# ESP32-S2 register map
Vendor: ESPRESSIF SYSTEMS (SHANGHAI) CO., LTD.; Series: ESP32 S-Series; File version: 20
CPU: Xtensa LX7 r0p0, little endian, no MPU, no FPU, 0 interrupt priority bits
Address unit: 32 bits
Registers are 32-bit, read-write, reset 0x0 unless marked. A register's access mark holds for its fields unless they carry their own. Offsets are from the block's base; [hi:lo] are bit positions.

## EXTMEM — External Memory
Base 0x61800000
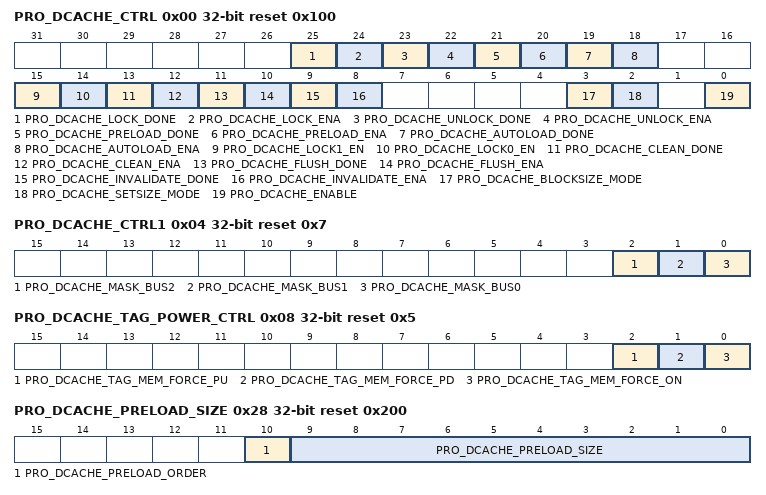
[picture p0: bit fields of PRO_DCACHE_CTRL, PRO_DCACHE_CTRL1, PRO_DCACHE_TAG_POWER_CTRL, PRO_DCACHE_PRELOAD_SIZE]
0x00 PRO_DCACHE_CTRL access per field reset 0x100 — register description
  [25] PRO_DCACHE_LOCK_DONE ro — The bit is used to indicate lock operation is finished.
  [24] PRO_DCACHE_LOCK_ENA rw — The bit is used to enable lock operation. It will be cleared by hardware after lock operation done.
  [23] PRO_DCACHE_UNLOCK_DONE ro — The bit is used to indicate unlock operation is finished.
  [22] PRO_DCACHE_UNLOCK_ENA rw — The bit is used to enable unlock operation. It will be cleared by hardware after unlock operation done.
  [21] PRO_DCACHE_PRELOAD_DONE ro — The bit is used to indicate preload operation is finished.
  [20] PRO_DCACHE_PRELOAD_ENA rw — The bit is used to enable preload operation. It will be cleared by hardware after preload operation done.
  [19] PRO_DCACHE_AUTOLOAD_DONE ro — The bit is used to indicate conditional-preload operation is finished.
  [18] PRO_DCACHE_AUTOLOAD_ENA rw — The bit is used to enable and disable conditional-preload operation. It is combined with pre_dcache_autoload_done. 1: enable, 0: disable.
  [15] PRO_DCACHE_LOCK1_EN rw — The bit is used to enable pre-lock operation which is combined with PRO_DCACHE_LOCK1_ADDR_REG and PRO_DCACHE_LOCK1_SIZE_REG.
  [14] PRO_DCACHE_LOCK0_EN rw — The bit is used to enable pre-lock operation which is combined with PRO_DCACHE_LOCK0_ADDR_REG and PRO_DCACHE_LOCK0_SIZE_REG.
  [13] PRO_DCACHE_CLEAN_DONE ro — The bit is used to indicate clean operation is finished.
  [12] PRO_DCACHE_CLEAN_ENA rw — The bit is used to enable clean operation. It will be cleared by hardware after clean operation done.
  [11] PRO_DCACHE_FLUSH_DONE ro — The bit is used to indicate flush operation is finished.
  [10] PRO_DCACHE_FLUSH_ENA rw — The bit is used to enable flush operation. It will be cleared by hardware after flush operation done.
  [9] PRO_DCACHE_INVALIDATE_DONE ro — The bit is used to indicate invalidate operation is finished.
  [8] PRO_DCACHE_INVALIDATE_ENA rw — The bit is used to enable invalidate operation. It will be cleared by hardware after invalidate operation done.
  [3] PRO_DCACHE_BLOCKSIZE_MODE rw — The bit is used to configure cache block size.0: 16 bytes, 1: 32 bytes
  [2] PRO_DCACHE_SETSIZE_MODE rw — The bit is used to configure cache memory size.0: 8KB, 1: 16KB
  [0] PRO_DCACHE_ENABLE rw — The bit is used to activate the data cache. 0: disable, 1: enable
0x04 PRO_DCACHE_CTRL1 reset 0x7 — register description
  [2] PRO_DCACHE_MASK_BUS2 — The bit is used to disable dbus2, 0: enable, 1: disable
  [1] PRO_DCACHE_MASK_BUS1 — The bit is used to disable dbus1, 0: enable, 1: disable
  [0] PRO_DCACHE_MASK_BUS0 — The bit is used to disable dbus0, 0: enable, 1: disable
0x08 PRO_DCACHE_TAG_POWER_CTRL reset 0x5 — register description
  [2] PRO_DCACHE_TAG_MEM_FORCE_PU — The bit is used to power dcache tag memory down, 0: follow rtc_lslp_pd, 1: power up
  [1] PRO_DCACHE_TAG_MEM_FORCE_PD — The bit is used to power dcache tag memory down, 0: follow rtc_lslp_pd, 1: power down
  [0] PRO_DCACHE_TAG_MEM_FORCE_ON — The bit is used to close clock gating of dcache tag memory. 1: close gating, 0: open clock gating.
0x0C PRO_DCACHE_LOCK0_ADDR — register description
  [31:0] PRO_DCACHE_LOCK0_ADDR — The bits are used to configure the first start virtual address of data locking, which is combined with PRO_DCACHE_LOCK0_SIZE_REG
0x10 PRO_DCACHE_LOCK0_SIZE — register description
  [15:0] PRO_DCACHE_LOCK0_SIZE — The bits are used to configure the first length of data locking, which is combined with PRO_DCACHE_LOCK0_ADDR_REG
0x14 PRO_DCACHE_LOCK1_ADDR — register description
  [31:0] PRO_DCACHE_LOCK1_ADDR — The bits are used to configure the second start virtual address of data locking, which is combined with PRO_DCACHE_LOCK1_SIZE_REG
0x18 PRO_DCACHE_LOCK1_SIZE — register description
  [15:0] PRO_DCACHE_LOCK1_SIZE — The bits are used to configure the second length of data locking, which is combined with PRO_DCACHE_LOCK1_ADDR_REG
0x1C PRO_DCACHE_MEM_SYNC0 — register description
  [31:0] PRO_DCACHE_MEMSYNC_ADDR — The bits are used to configure the start virtual address for invalidate, flush, clean, lock and unlock operations. The manual operations will be issued if the address is validate. The auto operations will be issued if the address is invalidate. It should be combined with PRO_DCACHE_MEM_SYNC1.
0x20 PRO_DCACHE_MEM_SYNC1 — register description
  [18:0] PRO_DCACHE_MEMSYNC_SIZE — The bits are used to configure the length for invalidate, flush, clean, lock and unlock operations. The manual operations will be issued if it is validate. The auto operations will be issued if it is invalidate. It should be combined with PRO_DCACHE_MEM_SYNC0.
0x24 PRO_DCACHE_PRELOAD_ADDR — register description
  [31:0] PRO_DCACHE_PRELOAD_ADDR — The bits are used to configure the start virtual address for manual pre-load operation. It should be combined with PRO_DCACHE_PRELOAD_SIZE_REG.
0x28 PRO_DCACHE_PRELOAD_SIZE reset 0x200 — register description
  [10] PRO_DCACHE_PRELOAD_ORDER — The bits are used to configure the direction of manual pre-load operation. 1: descending, 0: ascending.
  [9:0] PRO_DCACHE_PRELOAD_SIZE — The bits are used to configure the length for manual pre-load operation. It should be combined with PRO_DCACHE_PRELOAD_ADDR_REG..
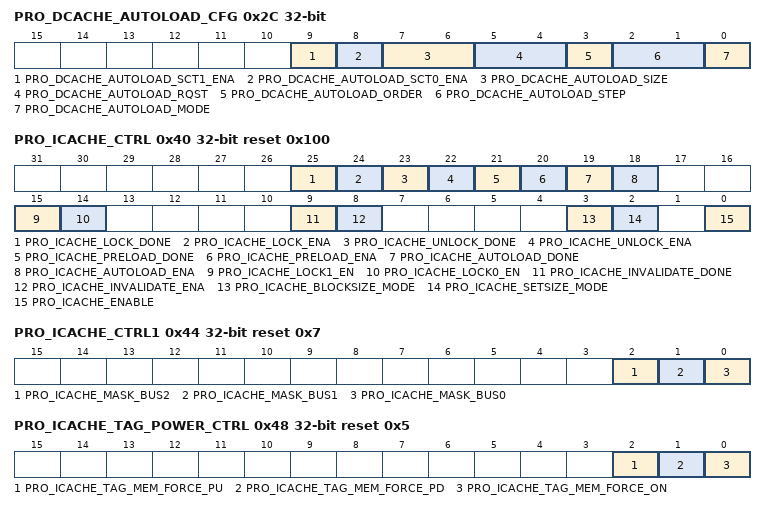
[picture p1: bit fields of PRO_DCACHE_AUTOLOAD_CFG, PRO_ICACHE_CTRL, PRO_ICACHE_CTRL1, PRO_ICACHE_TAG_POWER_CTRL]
0x2C PRO_DCACHE_AUTOLOAD_CFG — register description
  [9] PRO_DCACHE_AUTOLOAD_SCT1_ENA — The bits are used to enable the first section for conditional pre-load operation.
  [8] PRO_DCACHE_AUTOLOAD_SCT0_ENA — The bits are used to enable the second section for conditional pre-load operation.
  [7:6] PRO_DCACHE_AUTOLOAD_SIZE — The bits are used to configure the numbers of the cache block for the issuing conditional pre-load operation.
  [5:4] PRO_DCACHE_AUTOLOAD_RQST — The bits are used to configure trigger conditions for conditional pre-load. 0/3: cache miss, 1: cache hit, 2: both cache miss and hit.
  [3] PRO_DCACHE_AUTOLOAD_ORDER — The bits are used to configure the direction of conditional pre-load operation. 1: descending, 0: ascending.
  [2:1] PRO_DCACHE_AUTOLOAD_STEP — Reserved.
  [0] PRO_DCACHE_AUTOLOAD_MODE — Reserved.
0x30 PRO_DCACHE_AUTOLOAD_SECTION0_ADDR — register description
  [31:0] PRO_DCACHE_AUTOLOAD_SCT0_ADDR — The bits are used to configure the start virtual address of the first section for conditional pre-load operation. It should be combined with pro_dcache_autoload_sct0_ena.
0x34 PRO_DCACHE_AUTOLOAD_SECTION0_SIZE reset 0x8000 — register description
  [23:0] PRO_DCACHE_AUTOLOAD_SCT0_SIZE — The bits are used to configure the length of the first section for conditional pre-load operation. It should be combined with pro_dcache_autoload_sct0_ena.
0x38 PRO_DCACHE_AUTOLOAD_SECTION1_ADDR — register description
  [31:0] PRO_DCACHE_AUTOLOAD_SCT1_ADDR — The bits are used to configure the start virtual address of the second section for conditional pre-load operation. It should be combined with pro_dcache_autoload_sct1_ena.
0x3C PRO_DCACHE_AUTOLOAD_SECTION1_SIZE reset 0x8000 — register description
  [23:0] PRO_DCACHE_AUTOLOAD_SCT1_SIZE — The bits are used to configure the length of the second section for conditional pre-load operation. It should be combined with pro_dcache_autoload_sct1_ena.
0x40 PRO_ICACHE_CTRL access per field reset 0x100 — register description
  [25] PRO_ICACHE_LOCK_DONE ro — The bit is used to indicate lock operation is finished.
  [24] PRO_ICACHE_LOCK_ENA rw — The bit is used to enable lock operation. It will be cleared by hardware after lock operation done.
  [23] PRO_ICACHE_UNLOCK_DONE ro — The bit is used to indicate unlock operation is finished.
  [22] PRO_ICACHE_UNLOCK_ENA rw — The bit is used to enable unlock operation. It will be cleared by hardware after unlock operation done.
  [21] PRO_ICACHE_PRELOAD_DONE ro — The bit is used to indicate preload operation is finished.
  [20] PRO_ICACHE_PRELOAD_ENA rw — The bit is used to enable preload operation. It will be cleared by hardware after preload operation done.
  [19] PRO_ICACHE_AUTOLOAD_DONE ro — The bit is used to indicate conditional-preload operation is finished.
  [18] PRO_ICACHE_AUTOLOAD_ENA rw — The bit is used to enable and disable conditional-preload operation. It is combined with pre_dcache_autoload_done. 1: enable, 0: disable.
  [15] PRO_ICACHE_LOCK1_EN rw — The bit is used to enable pre-lock operation which is combined with PRO_ICACHE_LOCK1_ADDR_REG and PRO_ICACHE_LOCK1_SIZE_REG.
  [14] PRO_ICACHE_LOCK0_EN rw — The bit is used to enable pre-lock operation which is combined with PRO_ICACHE_LOCK0_ADDR_REG and PRO_ICACHE_LOCK0_SIZE_REG.
  [9] PRO_ICACHE_INVALIDATE_DONE ro — The bit is used to indicate invalidate operation is finished.
  [8] PRO_ICACHE_INVALIDATE_ENA rw — The bit is used to enable invalidate operation. It will be cleared by hardware after invalidate operation done.
  [3] PRO_ICACHE_BLOCKSIZE_MODE rw — The bit is used to configure cache block size.0: 16 bytes, 1: 32 bytes
  [2] PRO_ICACHE_SETSIZE_MODE rw — The bit is used to configure cache memory size.0: 8KB, 1: 16KB
  [0] PRO_ICACHE_ENABLE rw — The bit is used to activate the data cache. 0: disable, 1: enable
0x44 PRO_ICACHE_CTRL1 reset 0x7 — register description
  [2] PRO_ICACHE_MASK_BUS2 — The bit is used to disable ibus2, 0: enable, 1: disable
  [1] PRO_ICACHE_MASK_BUS1 — The bit is used to disable ibus1, 0: enable, 1: disable
  [0] PRO_ICACHE_MASK_BUS0 — The bit is used to disable ibus0, 0: enable, 1: disable
0x48 PRO_ICACHE_TAG_POWER_CTRL reset 0x5 — register description
  [2] PRO_ICACHE_TAG_MEM_FORCE_PU — The bit is used to power icache tag memory down, 0: follow rtc_lslp, 1: power up
  [1] PRO_ICACHE_TAG_MEM_FORCE_PD — The bit is used to power icache tag memory down, 0: follow rtc_lslp, 1: power down
  [0] PRO_ICACHE_TAG_MEM_FORCE_ON — The bit is used to close clock gating of icache tag memory. 1: close gating, 0: open clock gating.
0x4C PRO_ICACHE_LOCK0_ADDR — register description
  [31:0] PRO_ICACHE_LOCK0_ADDR — The bits are used to configure the first start virtual address of data locking, which is combined with PRO_ICACHE_LOCK0_SIZE_REG
0x50 PRO_ICACHE_LOCK0_SIZE — register description
  [15:0] PRO_ICACHE_LOCK0_SIZE — The bits are used to configure the first length of data locking, which is combined with PRO_ICACHE_LOCK0_ADDR_REG
0x54 PRO_ICACHE_LOCK1_ADDR — register description
  [31:0] PRO_ICACHE_LOCK1_ADDR — The bits are used to configure the second start virtual address of data locking, which is combined with PRO_ICACHE_LOCK1_SIZE_REG
0x58 PRO_ICACHE_LOCK1_SIZE — register description
  [15:0] PRO_ICACHE_LOCK1_SIZE — The bits are used to configure the second length of data locking, which is combined with PRO_ICACHE_LOCK1_ADDR_REG
0x5C PRO_ICACHE_MEM_SYNC0 — register description
  [31:0] PRO_ICACHE_MEMSYNC_ADDR — The bits are used to configure the start virtual address for invalidate, flush, clean, lock and unlock operations. The manual operations will be issued if the address is validate. The auto operations will be issued if the address is invalidate. It should be combined with PRO_ICACHE_MEM_SYNC1.
0x60 PRO_ICACHE_MEM_SYNC1 — register description
  [18:0] PRO_ICACHE_MEMSYNC_SIZE — The bits are used to configure the length for invalidate, flush, clean, lock and unlock operations. The manual operations will be issued if it is validate. The auto operations will be issued if it is invalidate. It should be combined with PRO_ICACHE_MEM_SYNC0.
0x64 PRO_ICACHE_PRELOAD_ADDR — register description
  [31:0] PRO_ICACHE_PRELOAD_ADDR — The bits are used to configure the start virtual address for manual pre-load operation. It should be combined with PRO_ICACHE_PRELOAD_SIZE_REG.
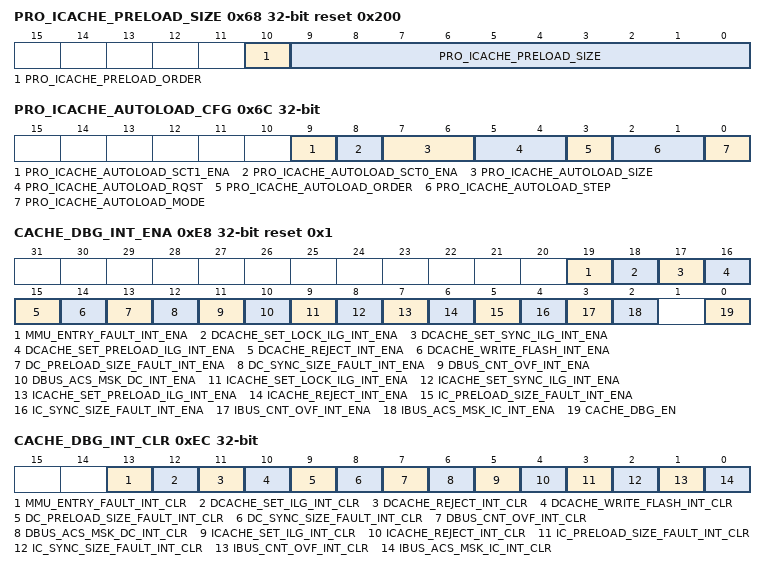
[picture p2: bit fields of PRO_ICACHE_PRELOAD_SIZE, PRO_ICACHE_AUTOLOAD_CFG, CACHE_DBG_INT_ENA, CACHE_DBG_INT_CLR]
0x68 PRO_ICACHE_PRELOAD_SIZE reset 0x200 — register description
  [10] PRO_ICACHE_PRELOAD_ORDER — The bits are used to configure the direction of manual pre-load operation. 1: descending, 0: ascending.
  [9:0] PRO_ICACHE_PRELOAD_SIZE — The bits are used to configure the length for manual pre-load operation. It should be combined with PRO_ICACHE_PRELOAD_ADDR_REG..
0x6C PRO_ICACHE_AUTOLOAD_CFG — register description
  [9] PRO_ICACHE_AUTOLOAD_SCT1_ENA — The bits are used to enable the first section for conditional pre-load operation.
  [8] PRO_ICACHE_AUTOLOAD_SCT0_ENA — The bits are used to enable the second section for conditional pre-load operation.
  [7:6] PRO_ICACHE_AUTOLOAD_SIZE — The bits are used to configure the numbers of the cache block for the issuing conditional pre-load operation.
  [5:4] PRO_ICACHE_AUTOLOAD_RQST — The bits are used to configure trigger conditions for conditional pre-load. 0/3: cache miss, 1: cache hit, 2: both cache miss and hit.
  [3] PRO_ICACHE_AUTOLOAD_ORDER — The bits are used to configure the direction of conditional pre-load operation. 1: descending, 0: ascending.
  [2:1] PRO_ICACHE_AUTOLOAD_STEP — Reserved.
  [0] PRO_ICACHE_AUTOLOAD_MODE — Reserved.
0x70 PRO_ICACHE_AUTOLOAD_SECTION0_ADDR — register description
  [31:0] PRO_ICACHE_AUTOLOAD_SCT0_ADDR — The bits are used to configure the start virtual address of the first section for conditional pre-load operation. It should be combined with pro_icache_autoload_sct0_ena.
0x74 PRO_ICACHE_AUTOLOAD_SECTION0_SIZE reset 0x8000 — register description
  [23:0] PRO_ICACHE_AUTOLOAD_SCT0_SIZE — The bits are used to configure the length of the first section for conditional pre-load operation. It should be combined with pro_icache_autoload_sct0_ena.
0x78 PRO_ICACHE_AUTOLOAD_SECTION1_ADDR — register description
  [31:0] PRO_ICACHE_AUTOLOAD_SCT1_ADDR — The bits are used to configure the start virtual address of the second section for conditional pre-load operation. It should be combined with pro_icache_autoload_sct1_ena.
0x7C PRO_ICACHE_AUTOLOAD_SECTION1_SIZE reset 0x8000 — register description
  [23:0] PRO_ICACHE_AUTOLOAD_SCT1_SIZE — The bits are used to configure the length of the second section for conditional pre-load operation. It should be combined with pro_icache_autoload_sct1_ena.
0x80 IC_PRELOAD_CNT ro — register description
  [15:0] IC_PRELOAD_CNT — The bits are used to count the number of issued pre-load which include manual pre-load and conditional pre-load.
0x84 IC_PRELOAD_MISS_CNT ro — register description
  [15:0] IC_PRELOAD_MISS_CNT — The bits are used to count the number of missed pre-load which include manual pre-load and conditional pre-load.
0x88 IBUS2_ABANDON_CNT ro — register description
  [15:0] IBUS2_ABANDON_CNT — The bits are used to count the number of the abandoned ibus2 access.
0x8C IBUS1_ABANDON_CNT ro — register description
  [15:0] IBUS1_ABANDON_CNT — The bits are used to count the number of the abandoned ibus1 access.
0x90 IBUS0_ABANDON_CNT ro — register description
  [15:0] IBUS0_ABANDON_CNT — The bits are used to count the number of the abandoned ibus0 access.
0x94 IBUS2_ACS_MISS_CNT ro — register description
  [31:0] IBUS2_ACS_MISS_CNT — The bits are used to count the number of the cache miss caused by ibus2 access.
0x98 IBUS1_ACS_MISS_CNT ro — register description
  [31:0] IBUS1_ACS_MISS_CNT — The bits are used to count the number of the cache miss caused by ibus1 access.
0x9C IBUS0_ACS_MISS_CNT ro — register description
  [31:0] IBUS0_ACS_MISS_CNT — The bits are used to count the number of the cache miss caused by ibus0 access.
0xA0 IBUS2_ACS_CNT ro — register description
  [31:0] IBUS2_ACS_CNT — The bits are used to count the number of ibus2 access icache.
0xA4 IBUS1_ACS_CNT ro — register description
  [31:0] IBUS1_ACS_CNT — The bits are used to count the number of ibus1 access icache.
0xA8 IBUS0_ACS_CNT ro — register description
  [31:0] IBUS0_ACS_CNT — The bits are used to count the number of ibus0 access icache.
0xAC DC_PRELOAD_CNT ro — register description
  [15:0] DC_PRELOAD_CNT — The bits are used to count the number of issued pre-load which include manual pre-load and conditional pre-load.
0xB0 DC_PRELOAD_EVICT_CNT ro — register description
  [15:0] DC_PRELOAD_EVICT_CNT — The bits are used to count the number of cache evictions by pre-load which include manual pre-load and conditional pre-load.
0xB4 DC_PRELOAD_MISS_CNT ro — register description
  [15:0] DC_PRELOAD_MISS_CNT — The bits are used to count the number of missed pre-load which include manual pre-load and conditional pre-load.
0xB8 DBUS2_ABANDON_CNT ro — register description
  [15:0] DBUS2_ABANDON_CNT — The bits are used to count the number of the abandoned dbus2 access.
0xBC DBUS1_ABANDON_CNT ro — register description
  [15:0] DBUS1_ABANDON_CNT — The bits are used to count the number of the abandoned dbus1 access.
0xC0 DBUS0_ABANDON_CNT ro — register description
  [15:0] DBUS0_ABANDON_CNT — The bits are used to count the number of the abandoned dbus0 access.
0xC4 DBUS2_ACS_WB_CNT ro — register description
  [19:0] DBUS2_ACS_WB_CNT — The bits are used to count the number of cache evictions by dbus2 access cache.
0xC8 DBUS1_ACS_WB_CNT ro — register description
  [19:0] DBUS1_ACS_WB_CNT — The bits are used to count the number of cache evictions by dbus1 access cache.
0xCC DBUS0_ACS_WB_CNT ro — register description
  [19:0] DBUS0_ACS_WB_CNT — The bits are used to count the number of cache evictions by dbus0 access cache.
0xD0 DBUS2_ACS_MISS_CNT ro — register description
  [31:0] DBUS2_ACS_MISS_CNT — The bits are used to count the number of the cache miss caused by dbus2 access.
0xD4 DBUS1_ACS_MISS_CNT ro — register description
  [31:0] DBUS1_ACS_MISS_CNT — The bits are used to count the number of the cache miss caused by dbus1 access.
0xD8 DBUS0_ACS_MISS_CNT ro — register description
  [31:0] DBUS0_ACS_MISS_CNT — The bits are used to count the number of the cache miss caused by dbus0 access.
0xDC DBUS2_ACS_CNT ro — register description
  [31:0] DBUS2_ACS_CNT — The bits are used to count the number of dbus2 access dcache.
0xE0 DBUS1_ACS_CNT ro — register description
  [31:0] DBUS1_ACS_CNT — The bits are used to count the number of dbus1 access dcache.
0xE4 DBUS0_ACS_CNT ro — register description
  [31:0] DBUS0_ACS_CNT — The bits are used to count the number of dbus0 access dcache.
0xE8 CACHE_DBG_INT_ENA reset 0x1 — register description
  [19] MMU_ENTRY_FAULT_INT_ENA — The bit is used to enable interrupt by mmu entry fault.
  [18] DCACHE_SET_LOCK_ILG_INT_ENA — The bit is used to enable interrupt by illegal writing lock registers of dcache while dcache is busy to issue lock,sync or pre-load operations.
  [17] DCACHE_SET_SYNC_ILG_INT_ENA — The bit is used to enable interrupt by illegal writing sync registers of dcache while dcache is busy to issue lock,sync and pre-load operations.
  [16] DCACHE_SET_PRELOAD_ILG_INT_ENA — The bit is used to enable interrupt by illegal writing preload registers of dcache while dcache is busy to issue lock,sync and pre-load operations.
  [15] DCACHE_REJECT_INT_ENA — The bit is used to enable interrupt by authentication fail.
  [14] DCACHE_WRITE_FLASH_INT_ENA — The bit is used to enable interrupt by dcache trying to write flash.
  [13] DC_PRELOAD_SIZE_FAULT_INT_ENA — The bit is used to enable interrupt by manual pre-load configurations fault.
  [12] DC_SYNC_SIZE_FAULT_INT_ENA — The bit is used to enable interrupt by manual sync configurations fault.
  [11] DBUS_CNT_OVF_INT_ENA — The bit is used to enable interrupt by dbus counter overflow.
  [10] DBUS_ACS_MSK_DC_INT_ENA — The bit is used to enable interrupt by cpu access dcache while the corresponding dbus is disabled which include speculative access.
  [9] ICACHE_SET_LOCK_ILG_INT_ENA — The bit is used to enable interrupt by illegal writing lock registers of icache while icache is busy to issue lock,sync or pre-load operations.
  [8] ICACHE_SET_SYNC_ILG_INT_ENA — The bit is used to enable interrupt by illegal writing sync registers of icache while icache is busy to issue lock,sync and pre-load operations.
  [7] ICACHE_SET_PRELOAD_ILG_INT_ENA — The bit is used to enable interrupt by illegal writing preload registers of icache while icache is busy to issue lock,sync and pre-load operations.
  [6] ICACHE_REJECT_INT_ENA — The bit is used to enable interrupt by authentication fail.
  [5] IC_PRELOAD_SIZE_FAULT_INT_ENA — The bit is used to enable interrupt by manual pre-load configurations fault.
  [4] IC_SYNC_SIZE_FAULT_INT_ENA — The bit is used to enable interrupt by manual sync configurations fault.
  [3] IBUS_CNT_OVF_INT_ENA — The bit is used to enable interrupt by ibus counter overflow.
  [2] IBUS_ACS_MSK_IC_INT_ENA — The bit is used to enable interrupt by cpu access icache while the corresponding ibus is disabled which include speculative access.
  [0] CACHE_DBG_EN — The bit is used to activate the cache track function. 1: enable, 0: disable.
0xEC CACHE_DBG_INT_CLR wo — register description
  [13] MMU_ENTRY_FAULT_INT_CLR — The bit is used to clear interrupt by mmu entry fault.
  [12] DCACHE_SET_ILG_INT_CLR — The bit is used to clear interrupt by illegal writing lock registers of dcache while dcache is busy to issue lock,sync or pre-load operations.
  [11] DCACHE_REJECT_INT_CLR — The bit is used to clear interrupt by authentication fail.
  [10] DCACHE_WRITE_FLASH_INT_CLR — The bit is used to clear interrupt by dcache trying to write flash.
  [9] DC_PRELOAD_SIZE_FAULT_INT_CLR — The bit is used to clear interrupt by manual pre-load configurations fault.
  [8] DC_SYNC_SIZE_FAULT_INT_CLR — The bit is used to clear interrupt by manual sync configurations fault.
  [7] DBUS_CNT_OVF_INT_CLR — The bit is used to clear interrupt by dbus counter overflow.
  [6] DBUS_ACS_MSK_DC_INT_CLR — The bit is used to clear interrupt by cpu access dcache while the corresponding dbus is disabled or dcache is disabled which include speculative access.
  [5] ICACHE_SET_ILG_INT_CLR — The bit is used to clear interrupt by illegal writing lock registers of icache while icache is busy to issue lock,sync or pre-load operations.
  [4] ICACHE_REJECT_INT_CLR — The bit is used to clear interrupt by authentication fail.
  [3] IC_PRELOAD_SIZE_FAULT_INT_CLR — The bit is used to clear interrupt by manual pre-load configurations fault.
  [2] IC_SYNC_SIZE_FAULT_INT_CLR — The bit is used to clear interrupt by manual sync configurations fault.
  [1] IBUS_CNT_OVF_INT_CLR — The bit is used to clear interrupt by ibus counter overflow.
  [0] IBUS_ACS_MSK_IC_INT_CLR — The bit is used to clear interrupt by cpu access icache while the corresponding ibus is disabled or icache is disabled which include speculative access.
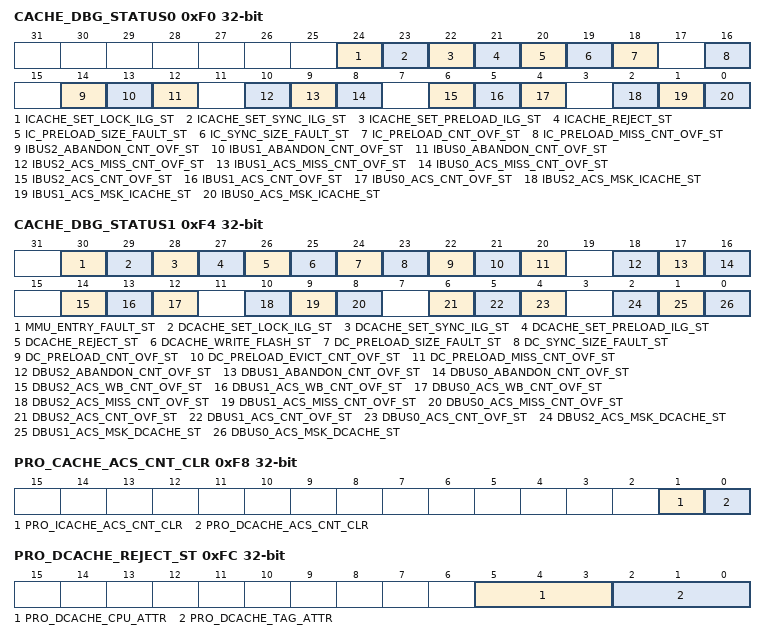
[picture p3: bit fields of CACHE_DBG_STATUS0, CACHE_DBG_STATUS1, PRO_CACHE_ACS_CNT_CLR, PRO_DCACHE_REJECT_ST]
0xF0 CACHE_DBG_STATUS0 ro — register description
  [24] ICACHE_SET_LOCK_ILG_ST — The bit is used to indicate interrupt by illegal writing lock registers of icache while icache is busy to issue lock,sync or pre-load operations.
  [23] ICACHE_SET_SYNC_ILG_ST — The bit is used to indicate interrupt by illegal writing sync registers of icache while icache is busy to issue lock,sync and pre-load operations.
  [22] ICACHE_SET_PRELOAD_ILG_ST — The bit is used to indicate interrupt by illegal writing preload registers of icache while icache is busy to issue lock,sync and pre-load operations.
  [21] ICACHE_REJECT_ST — The bit is used to indicate interrupt by authentication fail.
  [20] IC_PRELOAD_SIZE_FAULT_ST — The bit is used to indicate interrupt by manual pre-load configurations fault.
  [19] IC_SYNC_SIZE_FAULT_ST — The bit is used to indicate interrupt by manual sync configurations fault.
  [18] IC_PRELOAD_CNT_OVF_ST — The bit is used to indicate interrupt by pre-load counter overflow.
  [16] IC_PRELOAD_MISS_CNT_OVF_ST — The bit is used to indicate interrupt by pre-load miss counter overflow.
  [14] IBUS2_ABANDON_CNT_OVF_ST — The bit is used to indicate interrupt by ibus2 abandon counter overflow.
  [13] IBUS1_ABANDON_CNT_OVF_ST — The bit is used to indicate interrupt by ibus1 abandon counter overflow.
  [12] IBUS0_ABANDON_CNT_OVF_ST — The bit is used to indicate interrupt by ibus0 abandon counter overflow.
  [10] IBUS2_ACS_MISS_CNT_OVF_ST — The bit is used to indicate interrupt by ibus2 miss counter overflow.
  [9] IBUS1_ACS_MISS_CNT_OVF_ST — The bit is used to indicate interrupt by ibus1 miss counter overflow.
  [8] IBUS0_ACS_MISS_CNT_OVF_ST — The bit is used to indicate interrupt by ibus0 miss counter overflow.
  [6] IBUS2_ACS_CNT_OVF_ST — The bit is used to indicate interrupt by ibus2 counter overflow.
  [5] IBUS1_ACS_CNT_OVF_ST — The bit is used to indicate interrupt by ibus1 counter overflow.
  [4] IBUS0_ACS_CNT_OVF_ST — The bit is used to indicate interrupt by ibus0 counter overflow.
  [2] IBUS2_ACS_MSK_ICACHE_ST — The bit is used to indicate interrupt by cpu access icache while the ibus2 is disabled or icache is disabled which include speculative access.
  [1] IBUS1_ACS_MSK_ICACHE_ST — The bit is used to indicate interrupt by cpu access icache while the ibus1 is disabled or icache is disabled which include speculative access.
  [0] IBUS0_ACS_MSK_ICACHE_ST — The bit is used to indicate interrupt by cpu access icache while the ibus0 is disabled or icache is disabled which include speculative access.
0xF4 CACHE_DBG_STATUS1 ro — register description
  [30] MMU_ENTRY_FAULT_ST — The bit is used to indicate interrupt by mmu entry fault.
  [29] DCACHE_SET_LOCK_ILG_ST — The bit is used to indicate interrupt by illegal writing lock registers of icache while icache is busy to issue lock,sync or pre-load operations.
  [28] DCACHE_SET_SYNC_ILG_ST — The bit is used to indicate interrupt by illegal writing sync registers of icache while icache is busy to issue lock,sync and pre-load operations.
  [27] DCACHE_SET_PRELOAD_ILG_ST — The bit is used to indicate interrupt by illegal writing preload registers of icache while icache is busy to issue lock,sync and pre-load operations.
  [26] DCACHE_REJECT_ST — The bit is used to indicate interrupt by authentication fail.
  [25] DCACHE_WRITE_FLASH_ST — The bit is used to indicate interrupt by dcache trying to write flash.
  [24] DC_PRELOAD_SIZE_FAULT_ST — The bit is used to indicate interrupt by manual pre-load configurations fault.
  [23] DC_SYNC_SIZE_FAULT_ST — The bit is used to indicate interrupt by manual sync configurations fault.
  [22] DC_PRELOAD_CNT_OVF_ST — The bit is used to indicate interrupt by pre-load counter overflow.
  [21] DC_PRELOAD_EVICT_CNT_OVF_ST — The bit is used to indicate interrupt by pre-load eviction counter overflow.
  [20] DC_PRELOAD_MISS_CNT_OVF_ST — The bit is used to indicate interrupt by pre-load miss counter overflow.
  [18] DBUS2_ABANDON_CNT_OVF_ST — The bit is used to indicate interrupt by dbus2 abandon counter overflow.
  [17] DBUS1_ABANDON_CNT_OVF_ST — The bit is used to indicate interrupt by dbus1 abandon counter overflow.
  [16] DBUS0_ABANDON_CNT_OVF_ST — The bit is used to indicate interrupt by dbus0 abandon counter overflow.
  [14] DBUS2_ACS_WB_CNT_OVF_ST — The bit is used to indicate interrupt by dbus2 eviction counter overflow.
  [13] DBUS1_ACS_WB_CNT_OVF_ST — The bit is used to indicate interrupt by dbus1 eviction counter overflow.
  [12] DBUS0_ACS_WB_CNT_OVF_ST — The bit is used to indicate interrupt by dbus0 eviction counter overflow.
  [10] DBUS2_ACS_MISS_CNT_OVF_ST — The bit is used to indicate interrupt by dbus2 miss counter overflow.
  [9] DBUS1_ACS_MISS_CNT_OVF_ST — The bit is used to indicate interrupt by dbus1 miss counter overflow.
  [8] DBUS0_ACS_MISS_CNT_OVF_ST — The bit is used to indicate interrupt by dbus0 miss counter overflow.
  [6] DBUS2_ACS_CNT_OVF_ST — The bit is used to indicate interrupt by dbus2 counter overflow.
  [5] DBUS1_ACS_CNT_OVF_ST — The bit is used to indicate interrupt by dbus1 counter overflow.
  [4] DBUS0_ACS_CNT_OVF_ST — The bit is used to indicate interrupt by dbus0 counter overflow.
  [2] DBUS2_ACS_MSK_DCACHE_ST — The bit is used to indicate interrupt by cpu access dcache while the dbus2 is disabled or dcache is disabled which include speculative access.
  [1] DBUS1_ACS_MSK_DCACHE_ST — The bit is used to indicate interrupt by cpu access dcache while the dbus1 is disabled or dcache is disabled which include speculative access.
  [0] DBUS0_ACS_MSK_DCACHE_ST — The bit is used to indicate interrupt by cpu access dcache while the dbus0 is disabled or dcache is disabled which include speculative access.
0xF8 PRO_CACHE_ACS_CNT_CLR wo — register description
  [1] PRO_ICACHE_ACS_CNT_CLR — The bit is used to clear icache counter which include IC_PRELOAD_CNT_REG, IC_PRELOAD_MISS_CNT_REG, IBUS0-2_ABANDON_CNT_REG, IBUS0-2_ACS_MISS_CNT_REG and IBUS0-2_ACS_CNT_REG.
  [0] PRO_DCACHE_ACS_CNT_CLR — The bit is used to clear dcache counter which include DC_PRELOAD_CNT_REG, DC_PRELOAD_EVICT_CNT_REG, DC_PRELOAD_MISS_CNT_REG, DBUS0-2_ABANDON_CNT_REG, DBUS0-2_ACS_WB_CNT_REG, DBUS0-2_ACS_MISS_CNT_REG and DBUS0-2_ACS_CNT_REG.
0xFC PRO_DCACHE_REJECT_ST ro — register description
  [5:3] PRO_DCACHE_CPU_ATTR — The bits are used to indicate the attribute of CPU access dcache when authentication fail. 0: invalidate, 1: execute-able, 2: read-able, 4: write-able.
  [2:0] PRO_DCACHE_TAG_ATTR — The bits are used to indicate the attribute of data from external memory when authentication fail. 0: invalidate, 1: execute-able, 2: read-able, 4: write-able.
0x100 PRO_DCACHE_REJECT_VADDR ro — register description
  [31:0] PRO_DCACHE_CPU_VADDR — The bits are used to indicate the virtual address of CPU access dcache when authentication fail.
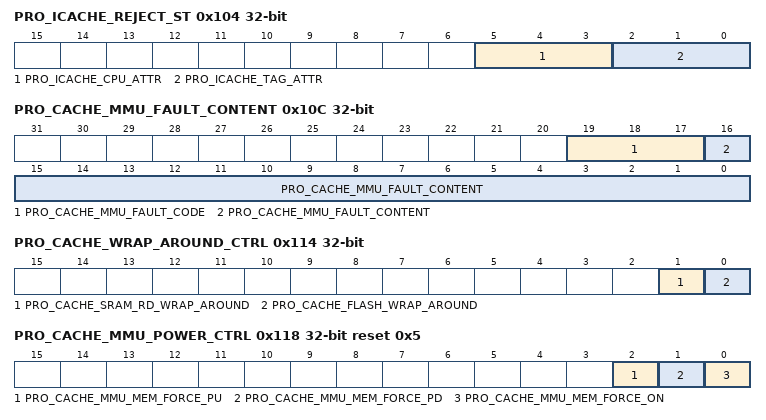
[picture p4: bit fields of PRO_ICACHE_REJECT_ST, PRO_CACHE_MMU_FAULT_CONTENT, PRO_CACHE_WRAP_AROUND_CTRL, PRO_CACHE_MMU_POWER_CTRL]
0x104 PRO_ICACHE_REJECT_ST ro — register description
  [5:3] PRO_ICACHE_CPU_ATTR — The bits are used to indicate the attribute of CPU access icache when authentication fail. 0: invalidate, 1: execute-able, 2: read-able
  [2:0] PRO_ICACHE_TAG_ATTR — The bits are used to indicate the attribute of data from external memory when authentication fail. 0: invalidate, 1: execute-able, 2: read-able, 4: write-able.
0x108 PRO_ICACHE_REJECT_VADDR ro — register description
  [31:0] PRO_ICACHE_CPU_VADDR — The bits are used to indicate the virtual address of CPU access icache when authentication fail.
0x10C PRO_CACHE_MMU_FAULT_CONTENT ro — register description
  [19:17] PRO_CACHE_MMU_FAULT_CODE — The bits are used to indicate the operations which cause mmu fault occurrence. 0: default, 1: cpu miss, 2: preload miss, 3: flush, 4: cpu miss evict recovery address, 5: load miss evict recovery address, 6: external dma tx, 7: external dma rx
  [16:0] PRO_CACHE_MMU_FAULT_CONTENT — The bits are used to indicate the content of mmu entry which cause mmu fault..
0x110 PRO_CACHE_MMU_FAULT_VADDR ro — register description
  [31:0] PRO_CACHE_MMU_FAULT_VADDR — The bits are used to indicate the virtual address which cause mmu fault..
0x114 PRO_CACHE_WRAP_AROUND_CTRL — register description
  [1] PRO_CACHE_SRAM_RD_WRAP_AROUND — The bit is used to enable wrap around mode when read data from spiram.
  [0] PRO_CACHE_FLASH_WRAP_AROUND — The bit is used to enable wrap around mode when read data from flash.
0x118 PRO_CACHE_MMU_POWER_CTRL reset 0x5 — register description
  [2] PRO_CACHE_MMU_MEM_FORCE_PU — The bit is used to power mmu memory down, 0: follow_rtc_lslp_pd, 1: power up
  [1] PRO_CACHE_MMU_MEM_FORCE_PD — The bit is used to power mmu memory down, 0: follow_rtc_lslp_pd, 1: power down
  [0] PRO_CACHE_MMU_MEM_FORCE_ON — The bit is used to enable clock gating to save power when access mmu memory, 0: enable, 1: disable
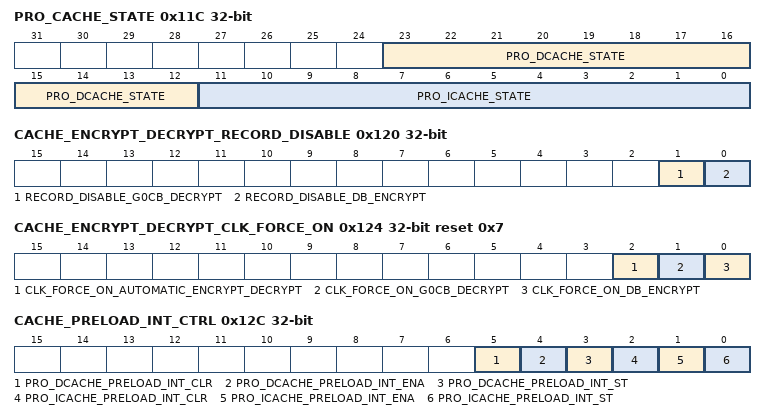
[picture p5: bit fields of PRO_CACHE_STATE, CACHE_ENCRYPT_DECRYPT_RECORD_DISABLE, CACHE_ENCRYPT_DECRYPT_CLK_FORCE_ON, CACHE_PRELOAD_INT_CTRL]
0x11C PRO_CACHE_STATE ro — register description
  [23:12] PRO_DCACHE_STATE — The bit is used to indicate dcache main fsm is in idle state or not. 1: in idle state, 0: not in idle state
  [11:0] PRO_ICACHE_STATE — The bit is used to indicate icache main fsm is in idle state or not. 1: in idle state, 0: not in idle state
0x120 CACHE_ENCRYPT_DECRYPT_RECORD_DISABLE — register description
  [1] RECORD_DISABLE_G0CB_DECRYPT — Reserved.
  [0] RECORD_DISABLE_DB_ENCRYPT — Reserved.
0x124 CACHE_ENCRYPT_DECRYPT_CLK_FORCE_ON reset 0x7 — register description
  [2] CLK_FORCE_ON_AUTOMATIC_ENCRYPT_DECRYPT — The bit is used to close clock gating of encrypt and decrypt clock. 1: close gating, 0: open clock gating.
  [1] CLK_FORCE_ON_G0CB_DECRYPT — The bit is used to close clock gating of decrypt clock. 1: close gating, 0: open clock gating.
  [0] CLK_FORCE_ON_DB_ENCRYPT — The bit is used to close clock gating of encrypt clock. 1: close gating, 0: open clock gating.
0x128 CACHE_BRIDGE_ARBITER_CTRL — register description
  [0] ALLOC_WB_HOLD_ARBITER — Reserved.
0x12C CACHE_PRELOAD_INT_CTRL access per field — register description
  [5] PRO_DCACHE_PRELOAD_INT_CLR wo — The bit is used to clear the interrupt by dcache pre-load done.
  [4] PRO_DCACHE_PRELOAD_INT_ENA rw — The bit is used to enable the interrupt by dcache pre-load done.
  [3] PRO_DCACHE_PRELOAD_INT_ST ro — The bit is used to indicate the interrupt by dcache pre-load done.
  [2] PRO_ICACHE_PRELOAD_INT_CLR wo — The bit is used to clear the interrupt by icache pre-load done.
  [1] PRO_ICACHE_PRELOAD_INT_ENA rw — The bit is used to enable the interrupt by icache pre-load done.
  [0] PRO_ICACHE_PRELOAD_INT_ST ro — The bit is used to indicate the interrupt by icache pre-load done.
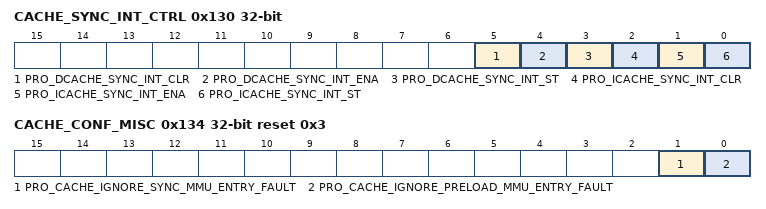
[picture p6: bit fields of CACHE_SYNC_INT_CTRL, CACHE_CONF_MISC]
0x130 CACHE_SYNC_INT_CTRL access per field — register description
  [5] PRO_DCACHE_SYNC_INT_CLR wo — The bit is used to clear the interrupt by dcache sync done.
  [4] PRO_DCACHE_SYNC_INT_ENA rw — The bit is used to enable the interrupt by dcache sync done.
  [3] PRO_DCACHE_SYNC_INT_ST ro — The bit is used to indicate the interrupt by dcache sync done.
  [2] PRO_ICACHE_SYNC_INT_CLR wo — The bit is used to clear the interrupt by icache sync done.
  [1] PRO_ICACHE_SYNC_INT_ENA rw — The bit is used to enable the interrupt by icache sync done.
  [0] PRO_ICACHE_SYNC_INT_ST ro — The bit is used to indicate the interrupt by icache sync done.
0x134 CACHE_CONF_MISC reset 0x3 — register description
  [1] PRO_CACHE_IGNORE_SYNC_MMU_ENTRY_FAULT — The bit is used to disable checking mmu entry fault by sync operation.
  [0] PRO_CACHE_IGNORE_PRELOAD_MMU_ENTRY_FAULT — The bit is used to disable checking mmu entry fault by preload operation.
0x138 CLOCK_GATE reset 0x1 — register description
  [0] CLK_EN — Reserved.
0x3FC PRO_EXTMEM_REG_DATE reset 0x1904180 — register description
  [27:0] PRO_EXTMEM_REG_DATE — Reserved.
